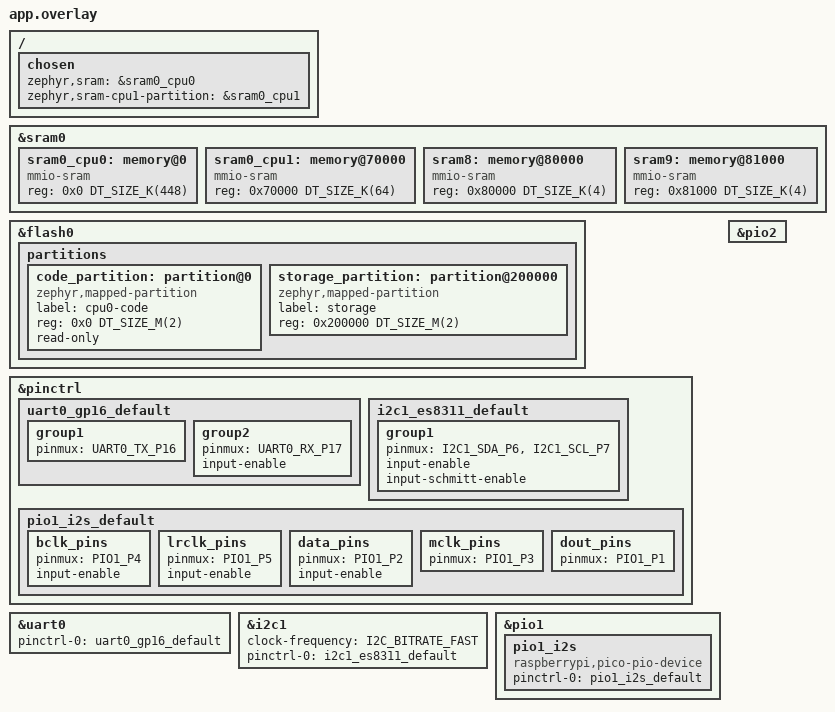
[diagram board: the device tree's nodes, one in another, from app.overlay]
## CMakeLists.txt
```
# SPDX-License-Identifier: Apache-2.0

cmake_minimum_required(VERSION 3.20.0)

set(MBEDTLS_FATAL_WARNINGS OFF CACHE BOOL "" FORCE)

include(${CMAKE_CURRENT_SOURCE_DIR}/modules/modules.cmake)
find_package(Zephyr REQUIRED HINTS $ENV{ZEPHYR_BASE})
project(pico_clip)

option(WIFI_SHELL_AMP_CPU0 "Build wifi_shell as the AMP CPU0 app" OFF)

zephyr_compile_options(-Wno-error=unused-parameter -Wno-error=unused-variable)
zephyr_compile_definitions(
  AIROC_WIFI_RX_PACKET_POOL_COUNT=32
  AIROC_WIFI_TX_PACKET_POOL_COUNT=16
  CONFIG_DTLS_USE_ECDSA=1
  CONFIG_DATA_BUFFER_SIZE=512
  CONFIG_AUDIO_BUFFER_SIZE=2048
  CONFIG_HTTP_BUFFER_SIZE=4096
  CONFIG_SDP_BUFFER_SIZE=4096
  CONFIG_MAX_NALU_SIZE=8192
  CONFIG_TLS_READ_TIMEOUT=30000
  CONFIG_STUN_KEEPALIVE_INTERVAL=5000
  CONFIG_STUN_KEEPALIVE_TIMEOUT=15000
)
zephyr_include_directories(${CMAKE_CURRENT_SOURCE_DIR}/src)
zephyr_include_directories(${CMAKE_CURRENT_SOURCE_DIR}/include)
zephyr_include_directories(${ZEPHYR_HAL_RPI_PICO_MODULE_DIR}/src/rp2_common/hardware_dma/include)
zephyr_include_directories(${CMAKE_CURRENT_SOURCE_DIR}/core1/src)
zephyr_include_directories(${CMAKE_CURRENT_SOURCE_DIR}/core1/src/audio_pio)
zephyr_include_directories(${CMAKE_CURRENT_SOURCE_DIR}/core1/src/audio_data)
zephyr_include_directories(${CMAKE_CURRENT_SOURCE_DIR}/core1/src/config)
zephyr_include_directories(${CMAKE_CURRENT_SOURCE_DIR}/core1/src/es8311)
zephyr_include_directories(${ZEPHYR_HAL_RPI_PICO_MODULE_DIR}/src/common/pico_stdlib_headers/include)
zephyr_include_directories(${ZEPHYR_HAL_RPI_PICO_MODULE_DIR}/src/rp2_common/hardware_i2c/include)
zephyr_include_directories(${ZEPHYR_HAL_RPI_PICO_MODULE_DIR}/src/rp2_common/hardware_spi/include)
zephyr_include_directories(${ZEPHYR_HAL_RPI_PICO_MODULE_DIR}/src/rp2_common/hardware_pwm/include)
zephyr_compile_definitions(PICO_CLIP_ZEPHYR_CORE1=1)

FILE(GLOB app_sources src/*.c)
target_sources(app PRIVATE ${app_sources})
target_sources(app PRIVATE ${ZEPHYR_HAL_RPI_PICO_MODULE_DIR}/src/rp2_common/hardware_dma/dma.c)
target_sources(app PRIVATE
  ${CMAKE_CURRENT_SOURCE_DIR}/core1/src/core1_audio.c
  ${CMAKE_CURRENT_SOURCE_DIR}/core1/src/core1_pcmu.c
  ${CMAKE_CURRENT_SOURCE_DIR}/core1/src/audio_pio/audio_pio.c
  ${CMAKE_CURRENT_SOURCE_DIR}/core1/src/audio_data/audio_data.c
  ${CMAKE_CURRENT_SOURCE_DIR}/core1/src/config/DEV_Config.c
  ${CMAKE_CURRENT_SOURCE_DIR}/core1/src/es8311/es8311.c
)
```

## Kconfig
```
mainmenu "Pico Clip Configuration"

source "Kconfig.zephyr"

menu "Pico Clip"

config WIFI_SSID
	string "Wi-Fi SSID"
	default ""
	help
	  SSID used for the automatic Wi-Fi connection.

config WIFI_PSK
	string "Wi-Fi pre-shared key"
	default ""
	help
	  Pre-shared key used for the automatic Wi-Fi connection.

config OPENAI_API_KEY
	string "OpenAI API key"
	default ""
	help
	  API key used as the default WebRTC signaling bearer token. The
	  webrtc_test command's -t option overrides this value. This value is
	  compiled into the firmware, so only use it on trusted devices.

endmenu
```

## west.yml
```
manifest:
  remotes:
    - name: zephyrproject-rtos
      url-base: https://github.com/zephyrproject-rtos
    - name: sepfy
      url-base: https://github.com/sepfy

  projects:
    - name: zephyr
      remote: zephyrproject-rtos
      revision: v4.4.0
      import: true

    - name: libpeer
      remote: sepfy
      revision: robot
      path: modules/lib/libpeer
      submodules: true

    - name: libpeer-zephyr-deps
      remote: sepfy
      revision: main
      path: modules/lib/libpeer-deps
      submodules: true

  self:
    path: pico-clip
```

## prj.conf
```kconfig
CONFIG_EARLY_CONSOLE=y
CONFIG_REBOOT=y

CONFIG_NETWORKING=y
CONFIG_NET_SOCKETS=y
CONFIG_POSIX_API=y
CONFIG_DNS_RESOLVER=y
CONFIG_DNS_SERVER_IP_ADDRESSES=y
CONFIG_DNS_SERVER1="8.8.8.8"
CONFIG_DNS_SERVER2="1.1.1.1"
CONFIG_MBEDTLS=y
CONFIG_PSA_CRYPTO=y
CONFIG_MBEDTLS_PSA_CRYPTO_C=y
CONFIG_TEST_RANDOM_GENERATOR=y
CONFIG_MBEDTLS_PSA_CRYPTO_LEGACY_RNG=y
CONFIG_MBEDTLS_SSL_PROTO_TLS1_2=y
# Match the Pico FreeRTOS libpeer sample: mqtts/DTLS are TLS 1.2 paths.
CONFIG_MBEDTLS_SSL_PROTO_TLS1_3=n
CONFIG_MBEDTLS_SSL_TLS1_3_KEY_EXCHANGE_MODE_EPHEMERAL_ENABLED=n
CONFIG_MBEDTLS_MD_C=y
CONFIG_MBEDTLS_CTR_DRBG_C=y
CONFIG_MBEDTLS_ENTROPY_C=y
CONFIG_MBEDTLS_X509_CRT_PARSE_C=y
CONFIG_MBEDTLS_X509_RSASSA_PSS_SUPPORT=y
CONFIG_MBEDTLS_BASE64_C=y
CONFIG_MBEDTLS_PEM_PARSE_C=y
CONFIG_MBEDTLS_SSL_SERVER_NAME_INDICATION=y
CONFIG_MBEDTLS_SSL_PROTO_DTLS=y
CONFIG_MBEDTLS_CIPHERSUITE_TLS_ECDHE_ECDSA_WITH_AES_128_GCM_SHA256=y
CONFIG_MBEDTLS_CIPHERSUITE_TLS_ECDHE_RSA_WITH_AES_128_GCM_SHA256=y
CONFIG_MBEDTLS_CIPHERSUITE_TLS1_3_AES_128_GCM_SHA256=n
CONFIG_MBEDTLS_CIPHER_ALL_ENABLED=y
CONFIG_MBEDTLS_HASH_ALL_ENABLED=y
CONFIG_MBEDTLS_SSL_MAX_CONTENT_LEN=8192
CONFIG_MBEDTLS_VERSION_C=y
CONFIG_MBEDTLS_DEBUG=n
CONFIG_MBEDTLS_USER_CONFIG_FILE="mbedtls-libpeer-user-config.h"
CONFIG_MBEDTLS_X509_CRL_PARSE_C=y
CONFIG_MBEDTLS_X509_CSR_WRITE_C=y
CONFIG_MBEDTLS_X509_CRT_WRITE_C=y
CONFIG_MBEDTLS_PEM_WRITE_C=y
CONFIG_MBEDTLS_PK_WRITE_C=y
CONFIG_MBEDTLS_KEY_EXCHANGE_PSK_ENABLED=y
CONFIG_MBEDTLS_KEY_EXCHANGE_ECDHE_PSK_ENABLED=y
CONFIG_MBEDTLS_CIPHERSUITE_TLS_ECDHE_RSA_WITH_AES_128_CBC_SHA256=y
CONFIG_MBEDTLS_CIPHERSUITE_TLS_ECDHE_RSA_WITH_AES_256_GCM_SHA384=y
CONFIG_MBEDTLS_CIPHERSUITE_TLS_ECDHE_ECDSA_WITH_AES_256_GCM_SHA384=y
CONFIG_MBEDTLS_CIPHERSUITE_TLS_ECDHE_ECDSA_WITH_AES_128_CCM_8=y
CONFIG_MBEDTLS_CIPHERSUITE_TLS_ECDHE_PSK_WITH_AES_256_CBC_SHA384=y
CONFIG_MBEDTLS_CIPHERSUITE_TLS_PSK_WITH_AES_256_CBC_SHA384=y
CONFIG_MBEDTLS_CIPHERSUITE_TLS_PSK_WITH_AES_128_GCM_SHA256=y
CONFIG_MBEDTLS_CIPHERSUITE_TLS1_3_AES_256_GCM_SHA384=n
CONFIG_MBEDTLS_CIPHERSUITE_TLS1_3_CHACHA20_POLY1305_SHA256=n

CONFIG_MAIN_STACK_SIZE=12288
CONFIG_SYSTEM_WORKQUEUE_STACK_SIZE=4096
# mbedTLS uses libc calloc(), whose arena comes from the SRAM left after
# static allocations. Keep the Zephyr system heap modest so MQTT TLS and
# DTLS-SRTP have enough libc malloc arena for their SSL buffers.
CONFIG_HEAP_MEM_POOL_SIZE=16384
CONFIG_SHELL_STACK_SIZE=12288
CONFIG_NET_TX_STACK_SIZE=2048
CONFIG_NET_RX_STACK_SIZE=2048

CONFIG_GPIO=y
CONFIG_I2C=y
CONFIG_PINCTRL=y
CONFIG_PIO_RPI_PICO=y

CONFIG_NET_PKT_RX_COUNT=128
CONFIG_NET_PKT_TX_COUNT=48
CONFIG_NET_BUF_RX_COUNT=128
CONFIG_NET_BUF_TX_COUNT=64
CONFIG_NET_BUF_DATA_SIZE=512
CONFIG_NET_BUF_POOL_USAGE=y
CONFIG_NET_PKT_ALLOC_STATS=y
CONFIG_NET_MAX_CONN=32
CONFIG_NET_MAX_CONTEXTS=32
CONFIG_NET_CONTEXT_RCVBUF=y
CONFIG_NET_CONTEXT_SNDBUF=y

CONFIG_NET_DHCPV4=y

CONFIG_NET_IPV4=y
CONFIG_NET_IPV6=n

CONFIG_NET_TCP=y
CONFIG_NET_TCP_PKT_ALLOC_TIMEOUT=500

CONFIG_NET_LOG=y
CONFIG_INIT_STACKS=y
CONFIG_STACK_SENTINEL=y

CONFIG_NET_SHELL=y

CONFIG_NET_STATISTICS=y
CONFIG_NET_STATISTICS_PERIODIC_OUTPUT=n

CONFIG_WIFI=y
CONFIG_WIFI_LOG_LEVEL_ERR=y
CONFIG_NET_L2_WIFI_SHELL=y
CONFIG_OPENAI_API_KEY=""
# printing of scan results puts pressure on queues in new locking
# design in net_mgmt. So, use a higher timeout for a crowded
# environment.
CONFIG_NET_MGMT_EVENT_QUEUE_TIMEOUT=5000
CONFIG_NET_MGMT_EVENT_QUEUE_SIZE=16

CONFIG_CJSON=y
CONFIG_LIBSRTP=y
CONFIG_LIBPEER=y
CONFIG_PSA_WANT_KEY_TYPE_RSA_PUBLIC_KEY=y
CONFIG_PSA_WANT_KEY_TYPE_ECC_PUBLIC_KEY=y
CONFIG_PSA_WANT_KEY_TYPE_DERIVE=y
CONFIG_PSA_WANT_KEY_TYPE_RAW_DATA=y
CONFIG_PSA_WANT_KEY_TYPE_ECC_KEY_PAIR_DERIVE=y
CONFIG_PSA_WANT_ALG_HKDF=y
CONFIG_PSA_WANT_ALG_RSA_OAEP=y
CONFIG_PSA_WANT_ALG_RSA_PKCS1V15_CRYPT=y
CONFIG_PSA_WANT_ALG_TLS12_PSK_TO_MS=y
CONFIG_PSA_WANT_ECC_MONTGOMERY_255=y
CONFIG_PSA_WANT_ECC_SECP_R1_384=y
CONFIG_PSA_WANT_ECC_SECP_R1_521=y
CONFIG_PSA_WANT_DH_RFC7919_2048=y
CONFIG_PSA_WANT_DH_RFC7919_3072=y
CONFIG_PSA_WANT_DH_RFC7919_4096=y
CONFIG_PSA_WANT_DH_RFC7919_6144=y
CONFIG_PSA_WANT_DH_RFC7919_8192=y
CONFIG_PSA_WANT_KEY_TYPE_PASSWORD=y
CONFIG_PSA_WANT_KEY_TYPE_PASSWORD_HASH=y
CONFIG_PSA_WANT_KEY_TYPE_HMAC=y
```

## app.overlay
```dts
#include <zephyr/dt-bindings/i2c/i2c.h>
#include <mem.h>

&sram0 {
	#address-cells = <1>;
	#size-cells = <1>;
	ranges = <0x0 0x20000000 DT_SIZE_K(520)>;

	sram0_cpu0: memory@0 {
		compatible = "mmio-sram";
		reg = <0x0 DT_SIZE_K(448)>;
	};

	sram0_cpu1: memory@70000 {
		compatible = "mmio-sram";
		reg = <0x70000 DT_SIZE_K(64)>;
	};

	sram8: memory@80000 {
		compatible = "mmio-sram";
		reg = <0x80000 DT_SIZE_K(4)>;
	};

	sram9: memory@81000 {
		compatible = "mmio-sram";
		reg = <0x81000 DT_SIZE_K(4)>;
	};
};

/ {
	chosen {
		zephyr,sram = &sram0_cpu0;
		zephyr,sram-cpu1-partition = &sram0_cpu1;
	};
};

&flash0 {
	partitions {
		ranges;
		#address-cells = <1>;
		#size-cells = <1>;

		code_partition: partition@0 {
			compatible = "zephyr,mapped-partition";
			label = "cpu0-code";
			reg = <0x0 DT_SIZE_M(2)>;
			read-only;
		};

		storage_partition: partition@200000 {
			compatible = "zephyr,mapped-partition";
			label = "storage";
			reg = <0x200000 DT_SIZE_M(2)>;
		};
	};
};

&pinctrl {
	uart0_gp16_default: uart0_gp16_default {
		group1 {
			pinmux = <UART0_TX_P16>;
		};

		group2 {
			pinmux = <UART0_RX_P17>;
			input-enable;
		};
	};

	i2c1_es8311_default: i2c1_es8311_default {
		group1 {
			pinmux = <I2C1_SDA_P6>, <I2C1_SCL_P7>;
			input-enable;
			input-schmitt-enable;
		};
	};

	pio1_i2s_default: pio1_i2s_default {
		bclk_pins {
			pinmux = <PIO1_P4>;
			input-enable;
		};

		lrclk_pins {
			pinmux = <PIO1_P5>;
			input-enable;
		};

		data_pins {
			pinmux = <PIO1_P2>;
			input-enable;
		};

		mclk_pins {
			pinmux = <PIO1_P3>;
		};

		dout_pins {
			pinmux = <PIO1_P1>;
		};
	};
};

&uart0 {
	pinctrl-0 = <&uart0_gp16_default>;
	pinctrl-names = "default";
	status = "okay";
};

&i2c1 {
	clock-frequency = <I2C_BITRATE_FAST>;
	pinctrl-0 = <&i2c1_es8311_default>;
	pinctrl-names = "default";
	status = "okay";
};

&pio1 {
	status = "okay";

	pio1_i2s: pio1_i2s {
		compatible = "raspberrypi,pico-pio-device";
		pinctrl-0 = <&pio1_i2s_default>;
		pinctrl-names = "default";
		status = "okay";
	};
};

&pio2 {
	status = "okay";
};
```

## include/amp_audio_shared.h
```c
#ifndef WIFI_SHELL_AMP_AUDIO_SHARED_H_
#define WIFI_SHELL_AMP_AUDIO_SHARED_H_

#include <stdint.h>

#define AMP_AUDIO_SHARED_BASE 0x20078000u
#define AMP_AUDIO_SHARED_SIZE 0x8000u
#define AMP_AUDIO_CPU0_SRAM_BASE 0x20000000u
#define AMP_AUDIO_CPU0_SRAM_SIZE 0x60000u
#define AMP_AUDIO_CPU1_SRAM_BASE 0x20060000u
#define AMP_AUDIO_CPU1_SRAM_SIZE 0x18000u
#define AMP_AUDIO_RESERVED_BASE 0x20080000u
#define AMP_AUDIO_RESERVED_SIZE 0x2000u
#define AMP_AUDIO_CPU1_FLASH_BASE 0x10200000u
#define AMP_AUDIO_CPU1_FLASH_SIZE 0x40000u
#define AMP_AUDIO_OPUS_MAX_PACKET 400u
#define AMP_AUDIO_SPK_OPUS_QUEUE 4u

#define AMP_AUDIO_MAGIC 0x31445541u /* AUD1 */
#define AMP_AUDIO_VERSION 1u

#ifndef BIT
#define BIT(n) (1u << (n))
#endif

#define AMP_AUDIO_FLAG_OPUS_READY BIT(0)
#define AMP_AUDIO_FLAG_TEST_TONE BIT(1)
#define AMP_AUDIO_FLAG_PIO_MIC BIT(2)
#define AMP_AUDIO_FLAG_SPK_READY BIT(3)

enum amp_audio_state {
	AMP_AUDIO_STATE_BOOTING = 1,
	AMP_AUDIO_STATE_IDLE = 2,
	AMP_AUDIO_STATE_ERROR = 0xff,
};

struct amp_audio_shared {
	uint32_t magic;
	uint32_t version;
	uint32_t state;
	uint32_t heartbeat;
	uint32_t cpu1_sram_base;
	uint32_t cpu1_sram_size;
	uint32_t shared_base;
	uint32_t shared_size;
	uint32_t sample_rate;
	uint32_t channels;
	uint32_t frame_samples;
	uint32_t flags;
	uint32_t mic_frames;
	uint32_t mic_packets;
	uint32_t spk_packets;
	uint32_t spk_frames;
	uint32_t overrun_count;
	uint32_t underrun_count;
	int32_t last_error;
	uint32_t opus_seq;
	uint32_t opus_len;
	uint32_t opus_checksum;
	uint32_t opus_encode_us;
	uint32_t opus_max_encode_us;
	uint32_t opus_bitrate;
	uint32_t opus_dropped;
	uint32_t opus_encoder_size;
	uint8_t opus_packet[AMP_AUDIO_OPUS_MAX_PACKET];
	uint32_t mic_abs_avg;
	int32_t mic_min;
	int32_t mic_max;
	uint32_t mic_nonzero;
	uint32_t spk_opus_seq;
	uint32_t spk_opus_write_seq;
	uint32_t spk_opus_read_seq;
	uint32_t spk_opus_dropped;
	uint32_t spk_decode_us;
	uint32_t spk_max_decode_us;
	uint32_t spk_decoder_size;
	uint32_t spk_opus_len[AMP_AUDIO_SPK_OPUS_QUEUE];
	uint32_t spk_opus_slot_seq[AMP_AUDIO_SPK_OPUS_QUEUE];
	uint8_t spk_opus_packet[AMP_AUDIO_SPK_OPUS_QUEUE][AMP_AUDIO_OPUS_MAX_PACKET];
};

static inline volatile struct amp_audio_shared *amp_audio_shared_get(void)
{
	return (volatile struct amp_audio_shared *)AMP_AUDIO_SHARED_BASE;
}

#endif
```

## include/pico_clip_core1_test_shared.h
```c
/* SPDX-License-Identifier: Apache-2.0 */

#ifndef PICO_CLIP_CORE1_TEST_SHARED_H_
#define PICO_CLIP_CORE1_TEST_SHARED_H_

#include <stdint.h>

#ifndef BIT
#define BIT(n) (1u << (n))
#endif

#define PICO_CLIP_CORE1_TEST_SHM_BASE 0x20080000u
#define PICO_CLIP_CORE1_TEST_MAGIC 0x54314350u /* PC1T */
#define PICO_CLIP_CORE1_TEST_VERSION 6u

#define PICO_CLIP_CORE1_AUDIO_CMD_NONE 0u
#define PICO_CLIP_CORE1_AUDIO_CMD_BIRTHDAY 1u
#define PICO_CLIP_CORE1_AUDIO_CMD_STOP 2u

#define PICO_CLIP_CORE1_AUDIO_IDLE 0u
#define PICO_CLIP_CORE1_AUDIO_INIT 1u
#define PICO_CLIP_CORE1_AUDIO_PLAYING 2u
#define PICO_CLIP_CORE1_AUDIO_DONE 3u
#define PICO_CLIP_CORE1_AUDIO_ERROR 0xffu

#define PICO_CLIP_CORE1_AUDIO_FLAG_OPUS_READY BIT(0)
#define PICO_CLIP_CORE1_AUDIO_FLAG_SPK_READY BIT(1)

#define PICO_CLIP_CORE1_OPUS_SAMPLE_RATE 24000u
#define PICO_CLIP_CORE1_OPUS_CHANNELS 1u
#define PICO_CLIP_CORE1_OPUS_FRAME_SAMPLES 480u
#define PICO_CLIP_CORE1_OPUS_BITRATE 16000u
#define PICO_CLIP_CORE1_OPUS_MAX_PACKET 400u
#define PICO_CLIP_CORE1_SPK_OPUS_QUEUE 4u

struct pico_clip_core1_test_shared {
	uint32_t magic;
	uint32_t version;
	uint32_t cpu1_boot_count;
	uint32_t cpu0_audio_cmd_seq;
	uint32_t cpu0_audio_cmd;
	uint32_t cpu1_audio_ack_seq;
	uint32_t audio_state;
	int32_t audio_error;
	uint32_t audio_heartbeat;
	uint32_t audio_play_count;
	uint32_t audio_progress;
	uint32_t audio_flags;
	uint32_t opus_seq;
	uint32_t opus_len;
	uint32_t opus_silence;
	uint32_t opus_bitrate;
	uint32_t opus_encode_count;
	uint32_t opus_decode_count;
	uint32_t opus_dropped;
	uint32_t opus_encode_last_us;
	uint32_t opus_encode_max_us;
	uint32_t opus_decode_last_us;
	uint32_t opus_decode_max_us;
	uint32_t opus_decode_errors;
	uint32_t spk_opus_pending_max;
	uint32_t mic_enabled;
	uint32_t flash_pause_request;
	uint32_t flash_pause_ack;
	uint32_t bootsel_samples;
	uint32_t spk_opus_write_seq;
	uint32_t spk_opus_read_seq;
	uint32_t spk_opus_dropped;
	uint32_t spk_opus_len[PICO_CLIP_CORE1_SPK_OPUS_QUEUE];
	uint32_t spk_opus_slot_seq[PICO_CLIP_CORE1_SPK_OPUS_QUEUE];
	uint8_t opus_packet[PICO_CLIP_CORE1_OPUS_MAX_PACKET];
	uint8_t spk_opus_packet[PICO_CLIP_CORE1_SPK_OPUS_QUEUE][PICO_CLIP_CORE1_OPUS_MAX_PACKET];
};

static inline volatile struct pico_clip_core1_test_shared *pico_clip_core1_test_shm(void)
{
	return (volatile struct pico_clip_core1_test_shared *)PICO_CLIP_CORE1_TEST_SHM_BASE;
}

#endif /* PICO_CLIP_CORE1_TEST_SHARED_H_ */
```

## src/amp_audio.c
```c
#include <errno.h>
#include <string.h>

#include <zephyr/kernel.h>
#include <zephyr/shell/shell.h>
#include <zephyr/sys/atomic.h>

#include <opus.h>

#include "amp_audio_sample.h"
#include "amp_audio_shared.h"

#define AMP_AUDIO_TEST_FRAME_SAMPLES 320U
#define AMP_AUDIO_TEST_BITRATE 24000
#define AMP_AUDIO_TEST_ENCODER_BYTES 20480
#define AMP_AUDIO_TEST_STACK_SIZE 8192
#define AMP_AUDIO_TEST_PRIORITY 7

static atomic_t sample_play_enabled;
static uint8_t sample_opus_encoder_storage[AMP_AUDIO_TEST_ENCODER_BYTES] __aligned(8);
static OpusEncoder *const sample_opus_encoder =
	(OpusEncoder *)sample_opus_encoder_storage;
static uint8_t sample_opus_packet[AMP_AUDIO_OPUS_MAX_PACKET];
static int16_t sample_pcm_frame[AMP_AUDIO_TEST_FRAME_SAMPLES];
static uint32_t sample_frame_index;
static uint32_t sample_packets_sent;
static uint32_t sample_packets_dropped;
static int sample_last_error;

static const char *amp_audio_state_name(uint32_t state)
{
	switch (state) {
	case AMP_AUDIO_STATE_BOOTING:
		return "booting";
	case AMP_AUDIO_STATE_IDLE:
		return "idle";
	case AMP_AUDIO_STATE_ERROR:
		return "error";
	default:
		return "unknown";
	}
}

static int amp_audio_queue_speaker_opus(const uint8_t *data, uint32_t len)
{
	volatile struct amp_audio_shared *shared = amp_audio_shared_get();
	uint32_t write_seq;
	uint32_t read_seq;
	uint32_t slot;

	if (shared->magic != AMP_AUDIO_MAGIC ||
	    shared->version != AMP_AUDIO_VERSION ||
	    (shared->flags & AMP_AUDIO_FLAG_SPK_READY) == 0U) {
		return -ENODEV;
	}

	if (len == 0U || len > AMP_AUDIO_OPUS_MAX_PACKET) {
		return -EINVAL;
	}

	write_seq = shared->spk_opus_write_seq;
	read_seq = shared->spk_opus_read_seq;
	if ((write_seq - read_seq) >= AMP_AUDIO_SPK_OPUS_QUEUE) {
		return -EAGAIN;
	}

	slot = write_seq % AMP_AUDIO_SPK_OPUS_QUEUE;
	shared->spk_opus_slot_seq[slot] = 0;
	memcpy((void *)shared->spk_opus_packet[slot], data, len);
	shared->spk_opus_len[slot] = len;
	shared->spk_opus_slot_seq[slot] = write_seq + 1U;
	shared->spk_opus_write_seq = write_seq + 1U;
	shared->spk_opus_seq = write_seq + 1U;
	shared->spk_packets++;
	return 0;
}

static void amp_audio_sample_copy_frame(void)
{
	for (uint32_t i = 0; i < AMP_AUDIO_TEST_FRAME_SAMPLES; i++) {
		uint32_t sample_index = sample_frame_index + i;

		if (sample_index >= AMP_AUDIO_SAMPLE_COUNT) {
			sample_index -= AMP_AUDIO_SAMPLE_COUNT;
		}
		sample_pcm_frame[i] = amp_audio_sample[sample_index];
	}

	sample_frame_index += AMP_AUDIO_TEST_FRAME_SAMPLES;
	if (sample_frame_index >= AMP_AUDIO_SAMPLE_COUNT) {
		sample_frame_index -= AMP_AUDIO_SAMPLE_COUNT;
	}
}

static int amp_audio_sample_encoder_init(void)
{
	int ret;

	ret = opus_encoder_get_size(AMP_AUDIO_SAMPLE_CHANNELS);
	if (ret <= 0 || ret > (int)sizeof(sample_opus_encoder_storage)) {
		return ret <= 0 ? -EINVAL : -ENOMEM;
	}

	ret = opus_encoder_init(sample_opus_encoder, AMP_AUDIO_SAMPLE_RATE,
				AMP_AUDIO_SAMPLE_CHANNELS, OPUS_APPLICATION_AUDIO);
	if (ret != OPUS_OK) {
		return ret;
	}

	opus_encoder_ctl(sample_opus_encoder, OPUS_SET_BITRATE(AMP_AUDIO_TEST_BITRATE));
	opus_encoder_ctl(sample_opus_encoder, OPUS_SET_COMPLEXITY(1));
	opus_encoder_ctl(sample_opus_encoder, OPUS_SET_SIGNAL(OPUS_SIGNAL_MUSIC));
	return 0;
}

static void amp_audio_sample_player(void *a, void *b, void *c)
{
	ARG_UNUSED(a);
	ARG_UNUSED(b);
	ARG_UNUSED(c);

	sample_last_error = amp_audio_sample_encoder_init();
	while (sample_last_error != 0) {
		k_msleep(1000);
		sample_last_error = amp_audio_sample_encoder_init();
	}

	while (1) {
		int ret;

		if (!atomic_get(&sample_play_enabled)) {
			k_msleep(20);
			continue;
		}

		amp_audio_sample_copy_frame();
		ret = opus_encode(sample_opus_encoder, sample_pcm_frame,
				  AMP_AUDIO_TEST_FRAME_SAMPLES, sample_opus_packet,
				  sizeof(sample_opus_packet));
		if (ret < 0) {
			sample_last_error = ret;
			sample_packets_dropped++;
			k_msleep(20);
			continue;
		}

		for (int tries = 0; tries < 20; tries++) {
			sample_last_error =
				amp_audio_queue_speaker_opus(sample_opus_packet, (uint32_t)ret);
			if (sample_last_error == 0) {
				sample_packets_sent++;
				break;
			}
			k_msleep(1);
		}
		if (sample_last_error != 0) {
			sample_packets_dropped++;
		}

		k_msleep(20);
	}
}

K_THREAD_DEFINE(amp_audio_sample_tid, AMP_AUDIO_TEST_STACK_SIZE,
		amp_audio_sample_player, NULL, NULL, NULL,
		AMP_AUDIO_TEST_PRIORITY, 0, 0);

static int cmd_amp_audio(const struct shell *sh, size_t argc, char **argv)
{
	volatile struct amp_audio_shared *shared = amp_audio_shared_get();
	uint32_t heartbeat0;
	uint32_t heartbeat1;

	if (argc < 2) {
		shell_print(sh, "Usage: amp_audio status | tone <on|off> | playwav <on|off>");
		return -EINVAL;
	}

	if (shared->magic != AMP_AUDIO_MAGIC || shared->version != AMP_AUDIO_VERSION) {
		shell_error(sh, "audio core not ready: magic=0x%08x version=%u",
			    shared->magic, shared->version);
		return -ENODEV;
	}

	if (strcmp(argv[1], "tone") == 0) {
		ARG_UNUSED(argc);
		ARG_UNUSED(argv);
		shared->flags &= ~AMP_AUDIO_FLAG_TEST_TONE;
		atomic_clear(&sample_play_enabled);
		shell_error(sh, "speaker output disabled in this firmware");
		return -ENOTSUP;
	}

	if (strcmp(argv[1], "playwav") == 0) {
		ARG_UNUSED(argc);
		ARG_UNUSED(argv);
		shared->flags &= ~AMP_AUDIO_FLAG_TEST_TONE;
		atomic_clear(&sample_play_enabled);
		shell_error(sh, "speaker output disabled in this firmware");
		return -ENOTSUP;
	}

	if (argc != 2 || strcmp(argv[1], "status") != 0) {
		shell_print(sh, "Usage: amp_audio status | tone <on|off> | playwav <on|off>");
		return -EINVAL;
	}

	heartbeat0 = shared->heartbeat;
	k_busy_wait(2000);
	heartbeat1 = shared->heartbeat;

	shell_print(sh, "audio core: state=%s heartbeat=%u->%u %s",
		    amp_audio_state_name(shared->state), heartbeat0, heartbeat1,
		    heartbeat0 == heartbeat1 ? "stalled" : "running");
	shell_print(sh, "layout: cpu1_sram=0x%08x+0x%x shared=0x%08x+0x%x",
		    shared->cpu1_sram_base, shared->cpu1_sram_size,
		    shared->shared_base, shared->shared_size);
	shell_print(sh, "audio: rate=%u channels=%u frame=%u flags=0x%x err=%d",
		    shared->sample_rate, shared->channels, shared->frame_samples,
		    shared->flags, shared->last_error);
		shell_print(sh, "stats: mic_frames=%u mic_packets=%u spk_packets=%u spk_frames=%u overrun=%u underrun=%u",
			    shared->mic_frames, shared->mic_packets, shared->spk_packets,
			    shared->spk_frames, shared->overrun_count, shared->underrun_count);
		shell_print(sh, "mic: min=%d max=%d abs_avg=%u nonzero=%u",
			    shared->mic_min, shared->mic_max,
			    shared->mic_abs_avg, shared->mic_nonzero);
		shell_print(sh, "opus: seq=%u len=%u checksum=0x%08x encode_us=%u max_us=%u bitrate=%u dropped=%u enc_size=%u",
			    shared->opus_seq, shared->opus_len, shared->opus_checksum,
			    shared->opus_encode_us, shared->opus_max_encode_us,
		    shared->opus_bitrate, shared->opus_dropped,
		    shared->opus_encoder_size);
			shell_print(sh, "speaker: seq=%u pending=%u len=%u decode_us=%u max_us=%u dropped=%u dec_size=%u",
				    shared->spk_opus_seq,
				    shared->spk_opus_write_seq - shared->spk_opus_read_seq,
			    shared->spk_opus_len[shared->spk_opus_read_seq %
						 AMP_AUDIO_SPK_OPUS_QUEUE],
				    shared->spk_decode_us, shared->spk_max_decode_us,
				    shared->spk_opus_dropped, shared->spk_decoder_size);
			shell_print(sh, "playwav: enabled=%ld sent=%u dropped=%u err=%d frame=%u",
				    atomic_get(&sample_play_enabled), sample_packets_sent,
				    sample_packets_dropped, sample_last_error,
				    sample_frame_index);

	return 0;
}

SHELL_CMD_REGISTER(amp_audio, NULL, "AMP audio core status", cmd_amp_audio);
```

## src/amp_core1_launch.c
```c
// SPDX-License-Identifier: Apache-2.0

#include <stdint.h>

#include <zephyr/shell/shell.h>

#include <hardware/regs/psm.h>
#include <hardware/regs/sio.h>
#include <hardware/structs/psm.h>
#include <hardware/structs/sio.h>

#include "amp_audio_shared.h"

#define CPU1_VECTOR_TABLE AMP_AUDIO_CPU1_FLASH_BASE
#define CPU1_BOOT_TIMEOUT 1000000U

static bool fifo_pop(uint32_t *value)
{
	uint32_t timeout = CPU1_BOOT_TIMEOUT;

	while ((sio_hw->fifo_st & SIO_FIFO_ST_VLD_BITS) == 0U) {
		if (timeout-- == 0U) {
			return false;
		}
	}
	*value = sio_hw->fifo_rd;
	return true;
}

static bool fifo_push(uint32_t value)
{
	uint32_t timeout = CPU1_BOOT_TIMEOUT;

	while ((sio_hw->fifo_st & SIO_FIFO_ST_RDY_BITS) == 0U) {
		if (timeout-- == 0U) {
			return false;
		}
	}
	sio_hw->fifo_wr = value;
	__asm__ volatile("sev");
	return true;
}

static void fifo_drain(void)
{
	while ((sio_hw->fifo_st & SIO_FIFO_ST_VLD_BITS) != 0U) {
		(void)sio_hw->fifo_rd;
	}
	sio_hw->fifo_st = SIO_FIFO_ST_ROE_BITS | SIO_FIFO_ST_WOF_BITS;
}

static int core1_reset_to_bootrom(void)
{
	uint32_t value;

	psm_hw->frce_off |= PSM_FRCE_OFF_PROC1_BITS;
	while ((psm_hw->frce_off & PSM_FRCE_OFF_PROC1_BITS) == 0U) {
	}

	fifo_drain();
	psm_hw->frce_off &= ~PSM_FRCE_OFF_PROC1_BITS;

	if (!fifo_pop(&value) || value != 0U) {
		return -1;
	}
	return 0;
}

static int core1_launch_raw(uint32_t vector_table)
{
	const uint32_t sp = *(const uint32_t *)vector_table;
	const uint32_t entry = *(const uint32_t *)(vector_table + 4U);
	const uint32_t sequence[] = {0U, 0U, 1U, vector_table, sp, entry};
	uint32_t seq = 0;

	while (seq < ARRAY_SIZE(sequence)) {
		uint32_t response;
		uint32_t cmd = sequence[seq];

		if (cmd == 0U) {
			fifo_drain();
			__asm__ volatile("sev");
		}
		if (!fifo_push(cmd) || !fifo_pop(&response)) {
			return -1;
		}
		seq = (response == cmd) ? seq + 1U : 0U;
	}
	return 0;
}

static int cmd_core1_audio_start(const struct shell *sh, size_t argc, char **argv)
{
	volatile struct amp_audio_shared *shared = amp_audio_shared_get();
	int ret;

	ARG_UNUSED(argc);
	ARG_UNUSED(argv);

	shared->magic = 0;
	ret = core1_reset_to_bootrom();
	if (ret != 0) {
		shell_error(sh, "core1 reset failed");
		return ret;
	}
	ret = core1_launch_raw(CPU1_VECTOR_TABLE);
	if (ret != 0) {
		shell_error(sh, "core1 launch failed");
		return ret;
	}

	shell_print(sh, "core1 audio launched at 0x%08x", CPU1_VECTOR_TABLE);
	return 0;
}

static int cmd_core1_audio_status(const struct shell *sh, size_t argc, char **argv)
{
	volatile struct amp_audio_shared *shared = amp_audio_shared_get();

	ARG_UNUSED(argc);
	ARG_UNUSED(argv);

	shell_print(sh, "magic=0x%08x state=0x%x heartbeat=%u err=%d frames=%u rate=%u",
		    shared->magic, shared->state, shared->heartbeat, shared->last_error,
		    shared->spk_frames, shared->sample_rate);
	return 0;
}

SHELL_STATIC_SUBCMD_SET_CREATE(core1_audio_cmds,
	SHELL_CMD(start, NULL, "Launch CPU1 bare-metal ES8311 birthday player", cmd_core1_audio_start),
	SHELL_CMD(status, NULL, "Show CPU1 audio shared status", cmd_core1_audio_status),
	SHELL_SUBCMD_SET_END);

SHELL_CMD_REGISTER(core1_audio, &core1_audio_cmds, "CPU1 bare-metal audio", NULL);
```

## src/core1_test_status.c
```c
// SPDX-License-Identifier: Apache-2.0

#include <errno.h>
#include <string.h>

#include <zephyr/devicetree.h>
#include <zephyr/init.h>
#include <zephyr/kernel.h>
#include <zephyr/shell/shell.h>

#include <hardware/address_mapped.h>
#include <hardware/regs/io_qspi.h>
#include <hardware/regs/sio.h>
#include <hardware/structs/ioqspi.h>
#include <hardware/structs/psm.h>
#include <hardware/structs/sio.h>

#include "core1_audio.h"
#include "pico_clip_core1_test_shared.h"

#define CPU1_SRAM_ADDR DT_REG_ADDR(DT_CHOSEN(zephyr_sram_cpu1_partition))
#define CPU1_SRAM_SIZE DT_REG_SIZE(DT_CHOSEN(zephyr_sram_cpu1_partition))
#define CORE1_FIFO_TIMEOUT_LOOPS 100000U
#define CORE1_VECTOR_BYTES 0x100U
#define BOOTSEL_POLL_MS 10U
#define BOOTSEL_PAUSE_TIMEOUT_US 1000U

static __ramfunc bool bootsel_read(void)
{
	const uint32_t oe_mask = IO_QSPI_GPIO_QSPI_SS_CTRL_OEOVER_BITS;
	uint32_t primask;
	uint32_t ctrl;
	bool pressed;

	__asm volatile ("mrs %0, primask\ncpsid i" : "=r" (primask) :: "memory");
	ctrl = ioqspi_hw->io[1].ctrl;
	ioqspi_hw->io[1].ctrl =
		(ctrl & ~oe_mask) |
		(IO_QSPI_GPIO_QSPI_SS_CTRL_OEOVER_VALUE_DISABLE <<
		 IO_QSPI_GPIO_QSPI_SS_CTRL_OEOVER_LSB);
	for (volatile uint32_t i = 0; i < 1000u; i++) {
	}
	pressed = (sio_hw->gpio_hi_in & SIO_GPIO_HI_IN_QSPI_CSN_BITS) == 0u;
	ioqspi_hw->io[1].ctrl = ctrl;
	__asm volatile ("msr primask, %0" :: "r" (primask) : "memory");
	return pressed;
}

static bool wait_for_pause_ack(
	volatile struct pico_clip_core1_test_shared *shared, uint32_t token)
{
	for (uint32_t i = 0; i < BOOTSEL_PAUSE_TIMEOUT_US; i++) {
		if (shared->flash_pause_ack == token) return true;
		k_busy_wait(1);
	}
	return false;
}

static void bootsel_ptt_thread(void *p1, void *p2, void *p3)
{
	volatile struct pico_clip_core1_test_shared *shared = pico_clip_core1_test_shm();
	uint32_t token = 0u;

	ARG_UNUSED(p1);
	ARG_UNUSED(p2);
	ARG_UNUSED(p3);
	while (true) {
		if (shared->magic != PICO_CLIP_CORE1_TEST_MAGIC ||
		    shared->version != PICO_CLIP_CORE1_TEST_VERSION) {
			k_msleep(BOOTSEL_POLL_MS);
			continue;
		}
		token += 2u;
		shared->flash_pause_request = token;
		__DMB();
		__SEV();
		if (wait_for_pause_ack(shared, token)) {
			shared->mic_enabled = bootsel_read() ? 1u : 0u;
			shared->bootsel_samples++;
		}
		shared->flash_pause_request = token + 1u;
		__DMB();
		__SEV();
		(void)wait_for_pause_ack(shared, token + 1u);
		k_msleep(BOOTSEL_POLL_MS);
	}
}

K_THREAD_DEFINE(bootsel_ptt_tid, 1024, bootsel_ptt_thread,
		NULL, NULL, NULL, 7, 0, 500);

static inline bool core1_fifo_write_ready(void)
{
	return (sio_hw->fifo_st & SIO_FIFO_ST_RDY_BITS) != 0U;
}

static inline bool core1_fifo_read_valid(void)
{
	return (sio_hw->fifo_st & SIO_FIFO_ST_VLD_BITS) != 0U;
}

static void core1_fifo_drain(void)
{
	while (core1_fifo_read_valid()) {
		(void)sio_hw->fifo_rd;
	}
}

static int core1_fifo_put(uint32_t value)
{
	for (uint32_t i = 0; i < CORE1_FIFO_TIMEOUT_LOOPS; i++) {
		if (core1_fifo_write_ready()) {
			sio_hw->fifo_wr = value;
			__SEV();
			return 0;
		}
		k_busy_wait(1);
	}
	return -ETIMEDOUT;
}

static int core1_fifo_pop(uint32_t *value)
{
	for (uint32_t i = 0; i < CORE1_FIFO_TIMEOUT_LOOPS; i++) {
		if (core1_fifo_read_valid()) {
			*value = sio_hw->fifo_rd;
			return 0;
		}
		k_busy_wait(1);
	}
	return -ETIMEDOUT;
}

static int core1_reset(void)
{
	uint32_t reset_token;

	core1_fifo_drain();
	sio_hw->fifo_st = 0xffU;
	hw_set_bits(&psm_hw->frce_off, PSM_FRCE_OFF_PROC1_BITS);
	for (uint32_t i = 0; i < CORE1_FIFO_TIMEOUT_LOOPS; i++) {
		if ((psm_hw->frce_off & PSM_FRCE_OFF_PROC1_BITS) != 0U) {
			break;
		}
		if (i == CORE1_FIFO_TIMEOUT_LOOPS - 1U) {
			return -ETIMEDOUT;
		}
	}

	hw_clear_bits(&psm_hw->frce_off, PSM_FRCE_OFF_PROC1_BITS);
	if (core1_fifo_pop(&reset_token) != 0) {
		return -ETIMEDOUT;
	}
	return reset_token == 0U ? 0 : -EIO;
}

static int core1_boot(uint32_t vector_table, uint32_t sp, uint32_t pc)
{
	const uint32_t commands[] = { 0U, 0U, 1U, vector_table, sp, pc };

	for (uint32_t i = 0; i < ARRAY_SIZE(commands); i++) {
		uint32_t response;

		if (commands[i] == 0U) {
			core1_fifo_drain();
			sio_hw->fifo_st = 0xffU;
			__SEV();
		}
		if (core1_fifo_put(commands[i]) != 0) {
			return -ETIMEDOUT;
		}
		if (i == ARRAY_SIZE(commands) - 1U) {
			return 0;
		}
		if (core1_fifo_pop(&response) != 0 || response != commands[i]) {
			return -EIO;
		}
	}
	return 0;
}

static void __attribute__((noreturn, noinline)) core1_audio_worker(void)
{
	volatile struct pico_clip_core1_test_shared *shared = pico_clip_core1_test_shm();
	int ret;

	shared->magic = PICO_CLIP_CORE1_TEST_MAGIC;
	shared->version = PICO_CLIP_CORE1_TEST_VERSION;
	shared->cpu1_boot_count++;
	shared->audio_state = PICO_CLIP_CORE1_AUDIO_INIT;
	ret = core1_audio_run_pcmu_stream();
	shared->audio_error = ret;
	shared->audio_state = PICO_CLIP_CORE1_AUDIO_ERROR;

	while (true) {
		__asm volatile ("wfi");
	}
}

static int core1_audio_start(void)
{
	uint32_t *vector_table = (uint32_t *)CPU1_SRAM_ADDR;
	uint32_t sp = CPU1_SRAM_ADDR + CPU1_SRAM_SIZE - 8U;
	uint32_t pc = (uint32_t)core1_audio_worker | 1U;
	volatile struct pico_clip_core1_test_shared *shared = pico_clip_core1_test_shm();
	int ret;

	memset((void *)shared, 0, sizeof(*shared));
	memset(vector_table, 0, CORE1_VECTOR_BYTES);
	vector_table[0] = sp;
	vector_table[1] = pc;
	__DSB();
	__ISB();

	ret = core1_reset();
	if (ret != 0) {
		return ret;
	}
	return core1_boot((uint32_t)vector_table, sp, pc);
}

SYS_INIT(core1_audio_start, APPLICATION, 90);

static const char *audio_state_name(uint32_t state)
{
	switch (state) {
	case PICO_CLIP_CORE1_AUDIO_IDLE: return "idle";
	case PICO_CLIP_CORE1_AUDIO_INIT: return "init";
	case PICO_CLIP_CORE1_AUDIO_PLAYING: return "playing";
	case PICO_CLIP_CORE1_AUDIO_DONE: return "done";
	case PICO_CLIP_CORE1_AUDIO_ERROR: return "error";
	default: return "unknown";
	}
}

static int cmd_core1_audio_status(const struct shell *shell, size_t argc, char **argv)
{
	volatile struct pico_clip_core1_test_shared *shared = pico_clip_core1_test_shm();

	ARG_UNUSED(argc);
	ARG_UNUSED(argv);
	shell_print(shell,
		    "core1: magic=0x%08x version=%u boot=%u state=%s err=%d init_stage=%u",
		    shared->magic, shared->version, shared->cpu1_boot_count,
		    audio_state_name(shared->audio_state), shared->audio_error,
		    core1_audio_debug_stage);
	shell_print(shell,
		    "pcmu: seq=%u len=%u encoded=%u decoded=%u tx_drop=%u rx_drop=%u pending=%u bitrate=%u heartbeat=%u",
		    shared->opus_seq, shared->opus_len, shared->opus_encode_count,
		    shared->opus_decode_count, shared->opus_dropped,
		    shared->spk_opus_dropped,
		    shared->spk_opus_write_seq - shared->spk_opus_read_seq,
		    shared->opus_bitrate,
		    shared->audio_heartbeat);
	shell_print(shell,
		    "pcmu timing us: enc=%u max=%u dec=%u max=%u dec_err=%u queue_max=%u",
		    shared->opus_encode_last_us, shared->opus_encode_max_us,
		    shared->opus_decode_last_us, shared->opus_decode_max_us,
		    shared->opus_decode_errors, shared->spk_opus_pending_max);
	shell_print(shell, "ptt: bootsel=%s samples=%u pause=%u/%u",
		    shared->mic_enabled != 0u ? "pressed" : "released",
		    shared->bootsel_samples, shared->flash_pause_ack,
		    shared->flash_pause_request);
	return 0;
}

SHELL_CMD_REGISTER(core1_audio_status, NULL, "Show Core1 audio status",
		   cmd_core1_audio_status);

static int cmd_core1_audio(const struct shell *shell, size_t argc, char **argv)
{
	volatile struct pico_clip_core1_test_shared *shared = pico_clip_core1_test_shm();
	uint32_t command;

	if (argc != 2) {
		shell_error(shell, "usage: core1_audio <birthday|stop>");
		return -EINVAL;
	}
	if (strcmp(argv[1], "birthday") == 0) {
		command = PICO_CLIP_CORE1_AUDIO_CMD_BIRTHDAY;
	} else if (strcmp(argv[1], "stop") == 0) {
		command = PICO_CLIP_CORE1_AUDIO_CMD_STOP;
	} else {
		shell_error(shell, "unknown action: %s", argv[1]);
		return -EINVAL;
	}
	if (shared->magic != PICO_CLIP_CORE1_TEST_MAGIC ||
	    shared->version != PICO_CLIP_CORE1_TEST_VERSION) {
		shell_error(shell, "Core1 audio is not ready");
		return -EAGAIN;
	}
	shared->cpu0_audio_cmd = command;
	__DMB();
	shared->cpu0_audio_cmd_seq++;
	__DMB();
	__SEV();
	shell_print(shell, "Core1 audio %s requested (seq=%u)", argv[1],
		    shared->cpu0_audio_cmd_seq);
	return 0;
}

SHELL_CMD_REGISTER(core1_audio, NULL, "Control Core1 audio: birthday or stop",
		   cmd_core1_audio);
```

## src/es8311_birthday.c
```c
// SPDX-License-Identifier: Apache-2.0

#include <errno.h>
#include <stdbool.h>
#include <stdint.h>
#include <string.h>

#include <zephyr/device.h>
#include <zephyr/devicetree.h>
#include <zephyr/drivers/i2c.h>
#include <zephyr/drivers/misc/pio_rpi_pico/pio_rpi_pico.h>
#include <zephyr/drivers/pinctrl.h>
#include <zephyr/kernel.h>
#include <zephyr/shell/shell.h>
#include <zephyr/sys/util.h>

#include <hardware/clocks.h>
#include <hardware/dma.h>
#include <hardware/gpio.h>
#include <hardware/pio.h>
#include <hardware/regs/clocks.h>

#include "audio_pio.pio.h"

#define I2S_NODE DT_NODELABEL(pio1_i2s)

#define ES8311_ADDR 0x18
#define ES8311_I2C_RETRIES 5
#define ES8311_RESET_REG00 0x00
#define ES8311_CLK_MANAGER_REG01 0x01
#define ES8311_CLK_MANAGER_REG02 0x02
#define ES8311_CLK_MANAGER_REG03 0x03
#define ES8311_CLK_MANAGER_REG04 0x04
#define ES8311_CLK_MANAGER_REG05 0x05
#define ES8311_CLK_MANAGER_REG06 0x06
#define ES8311_CLK_MANAGER_REG07 0x07
#define ES8311_CLK_MANAGER_REG08 0x08
#define ES8311_SDPIN_REG09 0x09
#define ES8311_SDPOUT_REG0A 0x0a
#define ES8311_SYSTEM_REG0B 0x0b
#define ES8311_SYSTEM_REG0C 0x0c
#define ES8311_SYSTEM_REG0D 0x0d
#define ES8311_SYSTEM_REG0E 0x0e
#define ES8311_SYSTEM_REG10 0x10
#define ES8311_SYSTEM_REG11 0x11
#define ES8311_SYSTEM_REG12 0x12
#define ES8311_SYSTEM_REG13 0x13
#define ES8311_SYSTEM_REG14 0x14
#define ES8311_ADC_REG15 0x15
#define ES8311_ADC_REG16 0x16
#define ES8311_ADC_REG17 0x17
#define ES8311_ADC_REG1B 0x1b
#define ES8311_ADC_REG1C 0x1c
#define ES8311_DAC_REG31 0x31
#define ES8311_DAC_REG32 0x32
#define ES8311_DAC_REG37 0x37
#define ES8311_GPIO_REG44 0x44
#define ES8311_GP_REG45 0x45
#define ES8311_CHD1_REGFD 0xfd
#define ES8311_CHD2_REGFE 0xfe
#define ES8311_CHVER_REGFF 0xff

#define SAMPLE_RATE 24000U
#define MCLK_HZ (SAMPLE_RATE * 256U)
#define PA_CTRL_GPIO 0U
#define DOUT_GPIO 1U
#define DIN_GPIO 2U
#define MCLK_GPIO 3U
#define BCLK_GPIO 4U
#define LRCLK_GPIO 5U
#define BAT_EN_GPIO 28U
#define HAPPY_BIRTHDAY_SAMPLES 124800U
#define LOOPBACK_SAMPLES 4096U
#define PLAYER_STACK_SIZE 2048

static const struct device *const es8311_i2c_dev = DEVICE_DT_GET(DT_NODELABEL(i2c1));

extern const int16_t Happy_birsday[];

static PIO i2s_pio = pio2;
static PIO mclk_pio = pio1;
static PIO din_pio = pio1;
static uint i2s_sm = 0;
static uint mclk_sm = 2;
static uint din_sm = 1;
static uint tx_dma_channel;
static dma_channel_config tx_dma_config;
static int16_t loopback_buffer[LOOPBACK_SAMPLES];
static bool mclk_started;
static bool dma_ready;
static bool codec_i2c_ready;
static bool codec_ready;
static bool i2s_ready;
static bool din_ready;
static volatile bool player_running;
static volatile bool loopback_running;

K_THREAD_STACK_DEFINE(player_stack, PLAYER_STACK_SIZE);
static struct k_thread player_thread_data;
static k_tid_t player_thread_id;

static int es8311_write(uint8_t reg, uint8_t val)
{
	uint8_t buf[] = {reg, val};
	int ret = 0;

	for (int i = 0; i < ES8311_I2C_RETRIES; i++) {
		ret = i2c_write(es8311_i2c_dev, buf, sizeof(buf), ES8311_ADDR);
		if (ret == 0) {
			k_busy_wait(500);
			return 0;
		}
		k_msleep(2);
	}

	return ret < 0 ? ret : -EIO;
}

static int es8311_read(uint8_t reg, uint8_t *val)
{
	int ret = 0;

	for (int i = 0; i < ES8311_I2C_RETRIES; i++) {
		ret = i2c_write_read(es8311_i2c_dev, ES8311_ADDR, &reg, 1, val, 1);
		if (ret == 0) {
			k_busy_wait(500);
			return 0;
		}
		k_msleep(2);
	}

	return ret < 0 ? ret : -EIO;
}

static int es8311_update(uint8_t reg, uint8_t mask, uint8_t val)
{
	uint8_t old_val;
	int ret = es8311_read(reg, &old_val);

	if (ret < 0) {
		return ret;
	}
	return es8311_write(reg, (old_val & ~mask) | (val & mask));
}

static int es8311_i2c_start(void)
{
	if (codec_i2c_ready) {
		return 0;
	}

	if (!device_is_ready(es8311_i2c_dev)) {
		printk("i2c1 is not ready\n");
		return -ENODEV;
	}
	codec_i2c_ready = true;
	return 0;
}

static int es8311_init(void)
{
	uint8_t id1 = 0;
	uint8_t id2 = 0;
	uint8_t ver = 0;
	uint8_t reg00;
	uint8_t reg02;
	uint8_t reg06;
	int ret;

	ret = es8311_i2c_start();
	if (ret < 0) {
		return ret;
	}
	ret = es8311_read(ES8311_CHD1_REGFD, &id1);
	if (ret < 0) {
		return ret;
	}
	(void)es8311_read(ES8311_CHD2_REGFE, &id2);
	(void)es8311_read(ES8311_CHVER_REGFF, &ver);

	ret = es8311_write(ES8311_RESET_REG00, 0x1f);
	k_msleep(20);
	ret |= es8311_write(ES8311_RESET_REG00, 0x00);
	ret |= es8311_write(ES8311_RESET_REG00, 0x80);

	ret |= es8311_write(ES8311_CLK_MANAGER_REG01, 0x3f);
	ret |= es8311_read(ES8311_CLK_MANAGER_REG06, &reg06);
	reg06 &= ~BIT(5);
	reg06 |= 0x03;
	ret |= es8311_write(ES8311_CLK_MANAGER_REG06, reg06);

	ret |= es8311_read(ES8311_CLK_MANAGER_REG02, &reg02);
	reg02 &= 0x07;
	ret |= es8311_write(ES8311_CLK_MANAGER_REG02, reg02);
	ret |= es8311_write(ES8311_CLK_MANAGER_REG03, 0x10);
	ret |= es8311_write(ES8311_CLK_MANAGER_REG04, 0x10);
	ret |= es8311_write(ES8311_CLK_MANAGER_REG05, 0x00);
	ret |= es8311_read(ES8311_CLK_MANAGER_REG06, &reg06);
	reg06 &= 0xe0;
	reg06 |= 0x07;
	ret |= es8311_write(ES8311_CLK_MANAGER_REG06, reg06);
	ret |= es8311_update(ES8311_CLK_MANAGER_REG07, 0x3f, 0x00);
	ret |= es8311_write(ES8311_CLK_MANAGER_REG08, 0xff);

	ret |= es8311_read(ES8311_RESET_REG00, &reg00);
	reg00 |= 0x40;
	ret |= es8311_write(ES8311_RESET_REG00, reg00);
	ret |= es8311_write(ES8311_SDPIN_REG09, 0x0c);
	ret |= es8311_write(ES8311_SDPOUT_REG0A, 0x0c);

	ret |= es8311_write(ES8311_SYSTEM_REG0D, 0x01);
	ret |= es8311_write(ES8311_SYSTEM_REG0E, 0x02);
	ret |= es8311_write(ES8311_SYSTEM_REG12, 0x00);
	ret |= es8311_write(ES8311_SYSTEM_REG13, 0x10);
	ret |= es8311_write(ES8311_ADC_REG1C, 0x6a);
	ret |= es8311_write(ES8311_DAC_REG37, 0x08);
	ret |= es8311_write(ES8311_ADC_REG17, 0xff);
	ret |= es8311_write(ES8311_SYSTEM_REG14, 0x1a);
	ret |= es8311_write(ES8311_ADC_REG16, 0x03);
	ret |= es8311_write(ES8311_DAC_REG32, 0x98);
	ret |= es8311_update(ES8311_DAC_REG31, 0x60, 0x00);

	if (ret < 0) {
		return ret;
	}

	printk("ES8311 ready: id=%02x/%02x/%02x sample_rate=%u mclk=%u\n",
	       id1, id2, ver, SAMPLE_RATE, MCLK_HZ);
	codec_ready = true;
	return 0;
}

static float mclk_clock_div(void)
{
	return (float)clock_get_hz(clk_sys) / (float)(MCLK_HZ * mclk_pio_program.length);
}

static int i2s_start(void)
{
	uint32_t offset;

	if (i2s_ready) {
		return 0;
	}

	pio_sm_claim(i2s_pio, i2s_sm);
	offset = pio_add_program(i2s_pio, &audio_pio_program);
	audio_pio_program_init(i2s_pio, i2s_sm, offset, DOUT_GPIO, LRCLK_GPIO);
	pio_sm_set_clkdiv(i2s_pio, i2s_sm, 1.0f);
	pio_sm_clear_fifos(i2s_pio, i2s_sm);
	pio_sm_restart(i2s_pio, i2s_sm);
	pio_sm_set_enabled(i2s_pio, i2s_sm, true);
	i2s_ready = true;

	printk("ES8311 I2S ready: mclk=GP%u dout=GP%u din=GP%u bclk=GP%u lrclk=GP%u\n",
	       MCLK_GPIO, DOUT_GPIO, DIN_GPIO, BCLK_GPIO, LRCLK_GPIO);
	return 0;
}

static int din_start(void)
{
	uint32_t offset;

	if (din_ready) {
		return 0;
	}

	pio_sm_claim(din_pio, din_sm);
	offset = pio_add_program(din_pio, &read_pio_program);
	read_pio_program_init(din_pio, din_sm, offset, DIN_GPIO, LRCLK_GPIO);
	pio_sm_set_clkdiv(din_pio, din_sm, 1.0f);
	pio_sm_clear_fifos(din_pio, din_sm);
	pio_sm_restart(din_pio, din_sm);
	pio_sm_set_enabled(din_pio, din_sm, true);
	din_ready = true;
	return 0;
}

static void mclk_start(void)
{
	uint32_t offset;

	if (mclk_started) {
		return;
	}

	pio_sm_claim(mclk_pio, mclk_sm);
	offset = pio_add_program(mclk_pio, &mclk_pio_program);
	mclk_pio_program_init(mclk_pio, mclk_sm, offset, MCLK_GPIO);
	pio_sm_set_clkdiv(mclk_pio, mclk_sm, mclk_clock_div());
	pio_sm_clear_fifos(mclk_pio, mclk_sm);
	pio_sm_restart(mclk_pio, mclk_sm);
	pio_sm_set_enabled(mclk_pio, mclk_sm, true);
	mclk_started = true;
}

static int es8311_prepare(void)
{
	int ret;

	gpio_init(PA_CTRL_GPIO);
	gpio_set_dir(PA_CTRL_GPIO, GPIO_OUT);
	gpio_put(PA_CTRL_GPIO, 1);

	gpio_init(BAT_EN_GPIO);
	gpio_set_dir(BAT_EN_GPIO, GPIO_OUT);
	gpio_put(BAT_EN_GPIO, 1);

	if (!dma_ready) {
		tx_dma_channel = dma_claim_unused_channel(true);
		tx_dma_config = dma_channel_get_default_config(tx_dma_channel);
		channel_config_set_transfer_data_size(&tx_dma_config, DMA_SIZE_16);
		channel_config_set_read_increment(&tx_dma_config, true);
		channel_config_set_write_increment(&tx_dma_config, false);
		dma_ready = true;
	}

	mclk_start();
	k_msleep(20);

	if (!codec_ready) {
		ret = es8311_init();
		if (ret < 0) {
			return ret;
		}
	}

	return i2s_start();
}

static void birthday_worker(void *a, void *b, void *c)
{
	ARG_UNUSED(a);
	ARG_UNUSED(b);
	ARG_UNUSED(c);

	channel_config_set_dreq(&tx_dma_config, pio_get_dreq(i2s_pio, i2s_sm, true));

	while (player_running) {
		dma_channel_configure(tx_dma_channel,
				      &tx_dma_config,
				      &i2s_pio->txf[i2s_sm],
				      Happy_birsday,
				      HAPPY_BIRTHDAY_SAMPLES,
				      true);
		dma_channel_wait_for_finish_blocking(tx_dma_channel);
	}
	pio_sm_clear_fifos(i2s_pio, i2s_sm);
	player_running = false;
	player_thread_id = NULL;
}

static void loopback_worker(void *a, void *b, void *c)
{
	uint rx_dma_chan;
	uint tx_dma_chan;
	dma_channel_config rx_config;
	dma_channel_config tx_config;

	ARG_UNUSED(a);
	ARG_UNUSED(b);
	ARG_UNUSED(c);

	rx_dma_chan = dma_claim_unused_channel(true);
	rx_config = dma_channel_get_default_config(rx_dma_chan);
	channel_config_set_transfer_data_size(&rx_config, DMA_SIZE_16);
	channel_config_set_read_increment(&rx_config, false);
	channel_config_set_write_increment(&rx_config, true);
	channel_config_set_dreq(&rx_config, pio_get_dreq(din_pio, din_sm, false));

	tx_dma_chan = dma_claim_unused_channel(true);
	tx_config = dma_channel_get_default_config(tx_dma_chan);
	channel_config_set_transfer_data_size(&tx_config, DMA_SIZE_16);
	channel_config_set_read_increment(&tx_config, true);
	channel_config_set_write_increment(&tx_config, false);
	channel_config_set_dreq(&tx_config, pio_get_dreq(i2s_pio, i2s_sm, true));

	while (loopback_running) {
		dma_channel_configure(rx_dma_chan,
				      &rx_config,
				      loopback_buffer,
				      &din_pio->rxf[din_sm],
				      LOOPBACK_SAMPLES,
				      true);
		dma_channel_wait_for_finish_blocking(rx_dma_chan);
		if (!loopback_running) {
			break;
		}

		dma_channel_configure(tx_dma_chan,
				      &tx_config,
				      &i2s_pio->txf[i2s_sm],
				      loopback_buffer,
				      LOOPBACK_SAMPLES,
				      true);
		dma_channel_wait_for_finish_blocking(tx_dma_chan);
	}

	dma_channel_abort(rx_dma_chan);
	dma_channel_abort(tx_dma_chan);
	dma_channel_unclaim(rx_dma_chan);
	dma_channel_unclaim(tx_dma_chan);
	pio_sm_clear_fifos(din_pio, din_sm);
	pio_sm_clear_fifos(i2s_pio, i2s_sm);
	loopback_running = false;
	player_thread_id = NULL;
}

static int cmd_es8311_init(const struct shell *sh, size_t argc, char **argv)
{
	int ret;

	ARG_UNUSED(argc);
	ARG_UNUSED(argv);

	ret = es8311_prepare();
	if (ret < 0) {
		shell_error(sh, "ES8311 init failed: %d", ret);
		return ret;
	}

	shell_print(sh, "ES8311 ready");
	return 0;
}

static int cmd_es8311_birthday(const struct shell *sh, size_t argc, char **argv)
{
	int ret;

	ARG_UNUSED(argc);
	ARG_UNUSED(argv);

	if (player_running) {
		shell_print(sh, "birthday already playing");
		return 0;
	}
	if (loopback_running) {
		shell_error(sh, "loopback already running");
		return -EBUSY;
	}

	ret = es8311_prepare();
	if (ret < 0) {
		shell_error(sh, "ES8311 prepare failed: %d", ret);
		return ret;
	}

	pio_sm_clear_fifos(i2s_pio, i2s_sm);
	player_running = true;
	player_thread_id = k_thread_create(&player_thread_data, player_stack,
					   K_THREAD_STACK_SIZEOF(player_stack),
					   birthday_worker, NULL, NULL, NULL,
					   K_LOWEST_APPLICATION_THREAD_PRIO, 0,
					   K_NO_WAIT);
	shell_print(sh, "playing Happy Birthday");
	return 0;
}

static int cmd_es8311_loop(const struct shell *sh, size_t argc, char **argv)
{
	int ret;

	ARG_UNUSED(argc);
	ARG_UNUSED(argv);

	if (loopback_running) {
		shell_print(sh, "loopback already running");
		return 0;
	}
	if (player_running) {
		shell_error(sh, "birthday already playing");
		return -EBUSY;
	}

	ret = es8311_prepare();
	if (ret < 0) {
		shell_error(sh, "ES8311 prepare failed: %d", ret);
		return ret;
	}
	ret = din_start();
	if (ret < 0) {
		shell_error(sh, "ES8311 DIN prepare failed: %d", ret);
		return ret;
	}

	pio_sm_clear_fifos(din_pio, din_sm);
	pio_sm_clear_fifos(i2s_pio, i2s_sm);
	loopback_running = true;
	player_thread_id = k_thread_create(&player_thread_data, player_stack,
					   K_THREAD_STACK_SIZEOF(player_stack),
					   loopback_worker, NULL, NULL, NULL,
					   K_LOWEST_APPLICATION_THREAD_PRIO, 0,
					   K_NO_WAIT);
	shell_print(sh, "ES8311 loopback running");
	return 0;
}

static int cmd_es8311_micstat(const struct shell *sh, size_t argc, char **argv)
{
	uint rx_dma_chan;
	dma_channel_config rx_config;
	int16_t min_sample = INT16_MAX;
	int16_t max_sample = INT16_MIN;
	uint32_t nonzero = 0;
	uint32_t changed = 0;
	uint32_t timeout_ms = 300;
	int ret;

	ARG_UNUSED(argc);
	ARG_UNUSED(argv);

	if (player_running || loopback_running) {
		shell_error(sh, "stop playback/loopback first");
		return -EBUSY;
	}

	ret = es8311_prepare();
	if (ret < 0) {
		shell_error(sh, "ES8311 prepare failed: %d", ret);
		return ret;
	}
	ret = din_start();
	if (ret < 0) {
		shell_error(sh, "ES8311 DIN prepare failed: %d", ret);
		return ret;
	}

	memset(loopback_buffer, 0, sizeof(loopback_buffer));
	pio_sm_clear_fifos(din_pio, din_sm);

	rx_dma_chan = dma_claim_unused_channel(true);
	rx_config = dma_channel_get_default_config(rx_dma_chan);
	channel_config_set_transfer_data_size(&rx_config, DMA_SIZE_16);
	channel_config_set_read_increment(&rx_config, false);
	channel_config_set_write_increment(&rx_config, true);
	channel_config_set_dreq(&rx_config, pio_get_dreq(din_pio, din_sm, false));

	dma_channel_configure(rx_dma_chan,
			      &rx_config,
			      loopback_buffer,
			      &din_pio->rxf[din_sm],
			      LOOPBACK_SAMPLES,
			      true);

	while (dma_channel_is_busy(rx_dma_chan) && timeout_ms > 0) {
		k_msleep(1);
		timeout_ms--;
	}

	if (dma_channel_is_busy(rx_dma_chan)) {
		dma_channel_abort(rx_dma_chan);
		dma_channel_unclaim(rx_dma_chan);
		shell_error(sh, "mic RX timeout: no DIN samples within 300ms");
		return -ETIMEDOUT;
	}

	dma_channel_unclaim(rx_dma_chan);

	for (size_t i = 0; i < LOOPBACK_SAMPLES; i++) {
		int16_t sample = loopback_buffer[i];

		if (sample != 0) {
			nonzero++;
		}
		if (i > 0 && sample != loopback_buffer[i - 1]) {
			changed++;
		}
		if (sample < min_sample) {
			min_sample = sample;
		}
		if (sample > max_sample) {
			max_sample = sample;
		}
	}

	shell_print(sh, "mic samples=%u nonzero=%u changed=%u min=%d max=%d",
		    LOOPBACK_SAMPLES, nonzero, changed, min_sample, max_sample);
	return 0;
}

static int cmd_es8311_stop(const struct shell *sh, size_t argc, char **argv)
{
	ARG_UNUSED(argc);
	ARG_UNUSED(argv);

	player_running = false;
	loopback_running = false;
	if (dma_ready) {
		dma_channel_abort(tx_dma_channel);
	}
	k_msleep(5);
	if (din_ready) {
		pio_sm_clear_fifos(din_pio, din_sm);
	}
	if (i2s_ready) {
		pio_sm_clear_fifos(i2s_pio, i2s_sm);
	}
	shell_print(sh, "ES8311 audio stopped");
	return 0;
}

static int cmd_es8311_status(const struct shell *sh, size_t argc, char **argv)
{
	ARG_UNUSED(argc);
	ARG_UNUSED(argv);

	shell_print(sh, "mclk=%s codec=%s i2s=%s din=%s playback=%s loopback=%s samples=%u loop_samples=%u",
		    mclk_started ? "on" : "off",
		    codec_ready ? "ready" : "off",
		    i2s_ready ? "ready" : "off",
		    din_ready ? "ready" : "off",
		    player_running ? "running" : "stopped",
		    loopback_running ? "running" : "stopped",
		    HAPPY_BIRTHDAY_SAMPLES,
		    LOOPBACK_SAMPLES);
	return 0;
}

SHELL_STATIC_SUBCMD_SET_CREATE(es8311_cmds,
	SHELL_CMD(birthday, NULL, "Play Happy Birthday", cmd_es8311_birthday),
	SHELL_CMD(init, NULL, "Initialize ES8311 audio", cmd_es8311_init),
	SHELL_CMD(loop, NULL, "Run ES8311 loopback test", cmd_es8311_loop),
	SHELL_CMD(micstat, NULL, "Capture ES8311 mic stats", cmd_es8311_micstat),
	SHELL_CMD(status, NULL, "Show ES8311 audio state", cmd_es8311_status),
	SHELL_CMD(stop, NULL, "Stop ES8311 playback", cmd_es8311_stop),
	SHELL_SUBCMD_SET_END
);

SHELL_CMD_REGISTER(es8311, &es8311_cmds, "ES8311 audio", NULL);
```
